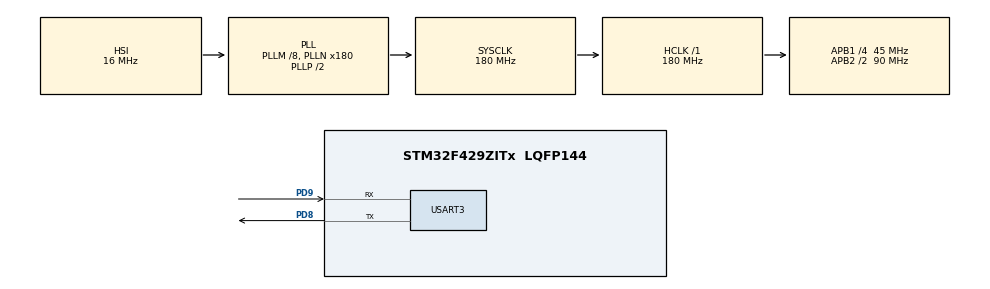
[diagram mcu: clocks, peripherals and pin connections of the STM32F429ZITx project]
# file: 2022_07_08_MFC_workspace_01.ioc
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Mcu.Family=STM32F4
Mcu.Name=STM32F429ZITx
Mcu.Package=LQFP144
NVIC.PriorityGroup=NVIC_PRIORITYGROUP_4
NVIC.USART3_IRQn=true\:0\:0\:false\:true\:true\:1\:true\:true\:true
PA13.Mode=Serial_Wire
PA13.Signal=SYS_JTMS-SWDIO
PA14.Mode=Serial_Wire
PA14.Signal=SYS_JTCK-SWCLK
PC14/OSC32_IN.Mode=LSE-External-Oscillator
PC14/OSC32_IN.Signal=RCC_OSC32_IN
PC15/OSC32_OUT.Mode=LSE-External-Oscillator
PC15/OSC32_OUT.Signal=RCC_OSC32_OUT
PD8.Mode=Asynchronous
PD8.Signal=USART3_TX
PD9.Mode=Asynchronous
PD9.Signal=USART3_RX
ProjectManager.HeapSize=0x200
ProjectManager.StackSize=0x400
ProjectManager.TargetToolchain=STM32CubeIDE
RCC.48MHZClocksFreq_Value=90000000
RCC.AHBFreq_Value=180000000
RCC.APB1CLKDivider=RCC_HCLK_DIV4
RCC.APB1Freq_Value=45000000
RCC.APB1TimFreq_Value=90000000
RCC.APB2CLKDivider=RCC_HCLK_DIV2
RCC.APB2Freq_Value=90000000
RCC.APB2TimFreq_Value=180000000
RCC.CortexFreq_Value=180000000
RCC.HCLKFreq_Value=180000000
RCC.HSE_VALUE=25000000
RCC.HSI_VALUE=16000000
RCC.PLLM=8
RCC.PLLN=180
RCC.RCC_RTC_Clock_Source=RCC_RTCCLKSOURCE_LSE
RCC.SYSCLKFreq_VALUE=180000000
RCC.SYSCLKSource=RCC_SYSCLKSOURCE_PLLCLK
RCC.VCOOutputFreq_Value=360000000
USART3.VirtualMode=VM_ASYNC
VP_RTC_VS_RTC_Activate.Mode=RTC_Enabled
board=custom

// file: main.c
/* USER CODE BEGIN Header */
/**
  ******************************************************************************
  * @file           : main.c
  * @brief          : Main program body
  ******************************************************************************
  * @attention
  *
  * Copyright (c) 2022 STMicroelectronics.
  * All rights reserved.
  *
  * This software is licensed under terms that can be found in the LICENSE file
  * in the root directory of this software component.
  * If no LICENSE file comes with this software, it is provided AS-IS.
  *
  ******************************************************************************
  */
/* USER CODE END Header */
#include "main.h"
#include "rtc.h"
#include "usart.h"
#include "gpio.h"

/* USER CODE BEGIN Includes */
#include "stdio.h"
#include <string.h>
/* USER CODE END Includes */

/* USER CODE BEGIN PV */
uint8_t rx;
/* USER CODE END PV */

void SystemClock_Config(void);
static void MX_NVIC_Init(void);

/* USER CODE BEGIN 0 */
int __io_puchar(int ch)
{
	HAL_UART_Transmit(&huart3, (uint8_t*)ch, 1, 100);
	return ch;
}
/* USER CODE END 0 */

int main(void)
{

  /* MCU Configuration--------------------------------------------------------*/

  /* Reset of all peripherals, Initializes the Flash interface and the Systick. */
  HAL_Init();

  /* Configure the system clock */
  SystemClock_Config();

  /* Initialize all configured peripherals */
  MX_GPIO_Init();
  MX_RTC_Init();
  MX_USART3_UART_Init();

  /* Initialize interrupts */
  MX_NVIC_Init();
  /* USER CODE BEGIN 2 */
  HAL_UART_Receive_IT(&huart3, &rx, 1);
  /* USER CODE END 2 */

  /* Infinite loop */
  while (1)
  {

  }
}

void SystemClock_Config(void)
{
  RCC_OscInitTypeDef RCC_OscInitStruct = {0};
  RCC_ClkInitTypeDef RCC_ClkInitStruct = {0};

  /** Configure the main internal regulator output voltage
  */
  __HAL_RCC_PWR_CLK_ENABLE();
  __HAL_PWR_VOLTAGESCALING_CONFIG(PWR_REGULATOR_VOLTAGE_SCALE1);

  /** Initializes the RCC Oscillators according to the specified parameters
  * in the RCC_OscInitTypeDef structure.
  */
  RCC_OscInitStruct.OscillatorType = RCC_OSCILLATORTYPE_HSI|RCC_OSCILLATORTYPE_LSE;
  RCC_OscInitStruct.LSEState = RCC_LSE_ON;
  RCC_OscInitStruct.HSIState = RCC_HSI_ON;
  RCC_OscInitStruct.HSICalibrationValue = RCC_HSICALIBRATION_DEFAULT;
  RCC_OscInitStruct.PLL.PLLState = RCC_PLL_ON;
  RCC_OscInitStruct.PLL.PLLSource = RCC_PLLSOURCE_HSI;
  RCC_OscInitStruct.PLL.PLLM = 8;
  RCC_OscInitStruct.PLL.PLLN = 180;
  RCC_OscInitStruct.PLL.PLLP = RCC_PLLP_DIV2;
  RCC_OscInitStruct.PLL.PLLQ = 4;
  if (HAL_RCC_OscConfig(&RCC_OscInitStruct) != HAL_OK)
  {
    Error_Handler();
  }

  /** Activate the Over-Drive mode
  */
  if (HAL_PWREx_EnableOverDrive() != HAL_OK)
  {
    Error_Handler();
  }

  /** Initializes the CPU, AHB and APB buses clocks
  */
  RCC_ClkInitStruct.ClockType = RCC_CLOCKTYPE_HCLK|RCC_CLOCKTYPE_SYSCLK
                              |RCC_CLOCKTYPE_PCLK1|RCC_CLOCKTYPE_PCLK2;
  RCC_ClkInitStruct.SYSCLKSource = RCC_SYSCLKSOURCE_PLLCLK;
  RCC_ClkInitStruct.AHBCLKDivider = RCC_SYSCLK_DIV1;
  RCC_ClkInitStruct.APB1CLKDivider = RCC_HCLK_DIV4;
  RCC_ClkInitStruct.APB2CLKDivider = RCC_HCLK_DIV2;

  if (HAL_RCC_ClockConfig(&RCC_ClkInitStruct, FLASH_LATENCY_5) != HAL_OK)
  {
    Error_Handler();
  }
}

/**
  * @brief NVIC Configuration.
  * @retval None
  */
static void MX_NVIC_Init(void)
{
  /* USART3_IRQn interrupt configuration */
  HAL_NVIC_SetPriority(USART3_IRQn, 0, 0);
  HAL_NVIC_EnableIRQ(USART3_IRQn);
}

/* USER CODE BEGIN 4 */
void HAL_UART_RxCpltCallback(UART_HandleTypeDef *huart)
{
	if(huart -> Instance == USART3)
	{
		if(rx >= 'A' && rx <= 'Z')
			rx += 32;
		else if(rx >= 'a' && rx <= 'z')
			rx -= 32;
		HAL_UART_Transmit(&huart3, &rx, 1, 100);
	}
	HAL_UART_Receive_IT(&huart3, &rx, 1);
}
/* USER CODE END 4 */

void Error_Handler(void)
{
  __disable_irq();
  while (1)
  {
  }
}
